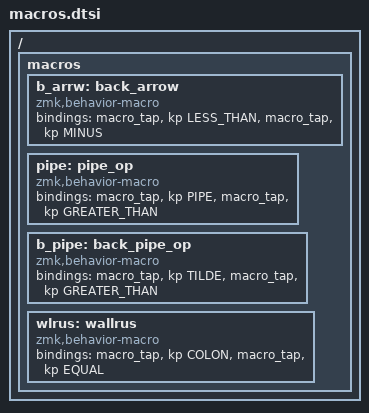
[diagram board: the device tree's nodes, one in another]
/ {
    macros {
         // PROGRAMMING SYNTAX
         /*s_arrw: slim_arrow { // ->
             compatible = "zmk,behavior-macro";
             #binding-cells = <0>;
             bindings =
                 <&macro_tap>,
                 <&kp MINUS>,
                 <&macro_tap>,
                 <&kp GREATER_THAN>;
         };*/

         b_arrw: back_arrow { // <-
             compatible = "zmk,behavior-macro";
             #binding-cells = <0>;
             bindings =
                 <&macro_tap>,
                 <&kp LESS_THAN>,
                 <&macro_tap>,
                 <&kp MINUS>;
         };

         /*f_arrw: fat_arrow { // =>
             compatible = "zmk,behavior-macro";
             #binding-cells = <0>;
             bindings =
                 <&macro_tap>,
                 <&kp EQUAL>,
                 <&macro_tap>,
                 <&kp GREATER_THAN>;
         };*/

         pipe: pipe_op { // |>
             compatible = "zmk,behavior-macro";
             #binding-cells = <0>;
             bindings =
                 <&macro_tap>,
                 <&kp PIPE>,
                 <&macro_tap>,
                 <&kp GREATER_THAN>;
         };

         b_pipe: back_pipe_op { // ~>
             compatible = "zmk,behavior-macro";
             #binding-cells = <0>;
             bindings =
                 <&macro_tap>,
                 <&kp TILDE>,
                 <&macro_tap>,
                 <&kp GREATER_THAN>;
         };

         wlrus: wallrus { // :=
             compatible = "zmk,behavior-macro";
             #binding-cells = <0>;
             bindings =
                 <&macro_tap>,
                 <&kp COLON>,
                 <&macro_tap>,
                 <&kp EQUAL>;
         };
    };
};
